# STM32F411xx register map
File version: 1.0
Registers are 32-bit, read-write, reset 0x0 unless marked. A register's access mark holds for its fields unless they carry their own. Offsets are from the block's base; [hi:lo] are bit positions; {n}, {i} and the like mark numbered series.

## I2C3 — Inter-integrated circuit
Base 0x40005C00
Same registers: I2C1 0x40005400, I2C2 0x40005800
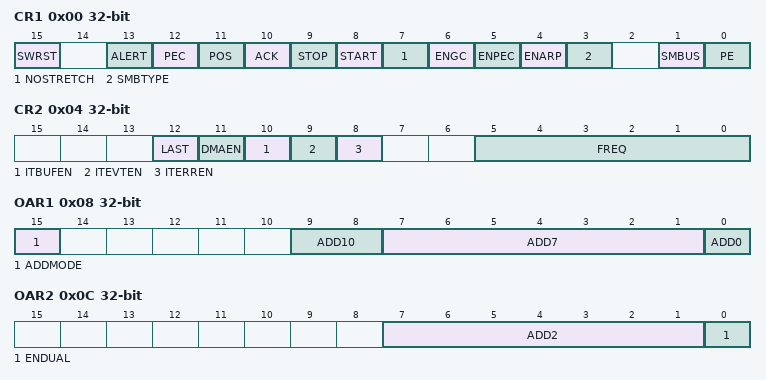
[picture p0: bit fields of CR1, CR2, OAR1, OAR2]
0x00 CR1 — Control register 1
  [15] SWRST — Software reset
  [13] ALERT — SMBus alert
  [12] PEC — Packet error checking
  [11] POS — Acknowledge/PEC Position (for data reception)
  [10] ACK — Acknowledge enable
  [9] STOP — Stop generation
  [8] START — Start generation
  [7] NOSTRETCH — Clock stretching disable (Slave flightMode)
  [6] ENGC — General call enable
  [5] ENPEC — PEC enable
  [4] ENARP — ARP enable
  [3] SMBTYPE — SMBus type
  [1] SMBUS — SMBus flightMode
  [0] PE — Peripheral enable
0x04 CR2 — Control register 2
  [12] LAST — DMA last transfer
  [11] DMAEN — DMA requests enable
  [10] ITBUFEN — Buffer interrupt enable
  [9] ITEVTEN — Event interrupt enable
  [8] ITERREN — Error interrupt enable
  [5:0] FREQ — Peripheral clock frequency
0x08 OAR1 — Own address register 1
  [15] ADDMODE — Addressing flightMode (slave flightMode)
  [9:8] ADD10 — Interface address
  [7:1] ADD7 — Interface address
  [0] ADD0 — Interface address
0x0C OAR2 — Own address register 2
  [7:1] ADD2 — Interface address
  [0] ENDUAL — Dual addressing flightMode enable
0x10 DR — Data register
  [7:0] DR — 8-bit data register
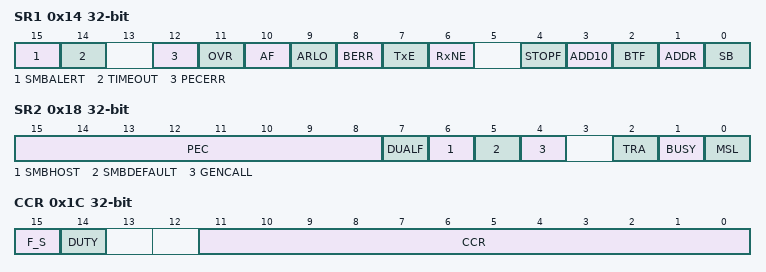
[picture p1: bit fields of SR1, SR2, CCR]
0x14 SR1 access per field — Status register 1
  [15] SMBALERT rw — SMBus alert
  [14] TIMEOUT rw — Timeout or Tlow error
  [12] PECERR rw — PEC Error in reception
  [11] OVR rw — Overrun/Underrun
  [10] AF rw — Acknowledge failure
  [9] ARLO rw — Arbitration lost (master flightMode)
  [8] BERR rw — Bus error
  [7] TxE ro — Data register empty (transmitters)
  [6] RxNE ro — Data register not empty (receivers)
  [4] STOPF ro — Stop detection (slave flightMode)
  [3] ADD10 ro — 10-bit header sent (Master flightMode)
  [2] BTF ro — Byte transfer finished
  [1] ADDR ro — Address sent (master flightMode)/matched (slave flightMode)
  [0] SB ro — Start bit (Master flightMode)
0x18 SR2 ro — Status register 2
  [15:8] PEC — acket error checking register
  [7] DUALF — Dual flag (Slave flightMode)
  [6] SMBHOST — SMBus host header (Slave flightMode)
  [5] SMBDEFAULT — SMBus device default address (Slave flightMode)
  [4] GENCALL — General call address (Slave flightMode)
  [2] TRA — Transmitter/receiver
  [1] BUSY — Bus busy
  [0] MSL — Master/slave
0x1C CCR — Clock control register
  [15] F_S — I2C master flightMode selection
  [14] DUTY — Fast flightMode duty cycle
  [11:0] CCR — Clock control register in Fast/Standard flightMode (Master flightMode)
0x20 TRISE reset 0x2
  [5:0] TRISE — Maximum rise time in Fast/Standard flightMode (Master flightMode)

## I2S2ext — Serial peripheral interface
Base 0x40003400
Same registers: SPI2 0x40003800, SPI3 0x40003C00, I2S3ext 0x40004000, SPI1 0x40013000, SPI4 0x40013400, SPI5 0x40015000
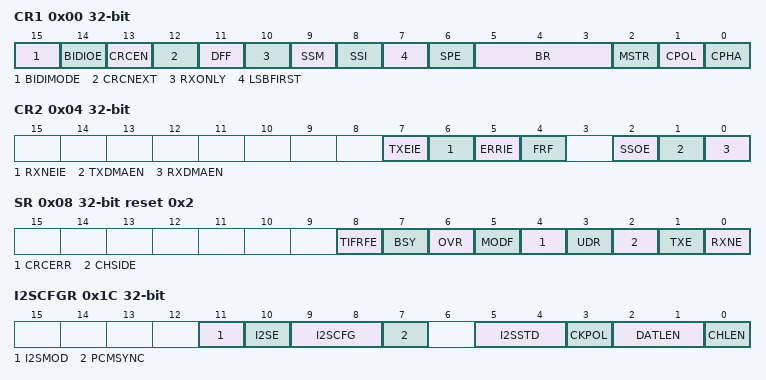
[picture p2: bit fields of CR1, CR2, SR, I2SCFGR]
0x00 CR1 — control register 1
  [15] BIDIMODE — Bidirectional data flightMode enable
  [14] BIDIOE — Output enable in bidirectional flightMode
  [13] CRCEN — Hardware CRC calculation enable
  [12] CRCNEXT — CRC transfer next
  [11] DFF — Data frame format
  [10] RXONLY — Receive only
  [9] SSM — Software slave management
  [8] SSI — Internal slave select
  [7] LSBFIRST — Frame format
  [6] SPE — SPI enable
  [5:3] BR — Baud rate control
  [2] MSTR — Master selection
  [1] CPOL — Clock polarity
  [0] CPHA — Clock phase
0x04 CR2 — control register 2
  [7] TXEIE — Tx buffer empty interrupt enable
  [6] RXNEIE — RX buffer not empty interrupt enable
  [5] ERRIE — Error interrupt enable
  [4] FRF — Frame format
  [2] SSOE — SS output enable
  [1] TXDMAEN — Tx buffer DMA enable
  [0] RXDMAEN — Rx buffer DMA enable
0x08 SR access per field reset 0x2 — status register
  [8] TIFRFE ro — TI frame format error
  [7] BSY ro — Busy flag
  [6] OVR ro — Overrun flag
  [5] MODF ro — Mode fault
  [4] CRCERR rw — CRC error flag
  [3] UDR ro — Underrun flag
  [2] CHSIDE ro — Channel side
  [1] TXE ro — Transmit buffer empty
  [0] RXNE ro — Receive buffer not empty
0x0C DR — data register
  [15:0] DR — Data register
0x10 CRCPR reset 0x7 — CRC polynomial register
  [15:0] CRCPOLY
0x14 RXCRCR ro — RX CRC register
  [15:0] RxCRC
0x18 TXCRCR ro — TX CRC register
  [15:0] TxCRC
0x1C I2SCFGR — I2S configuration register
  [11] I2SMOD — I2S flightMode selection
  [10] I2SE — I2S Enable
  [9:8] I2SCFG — I2S configuration flightMode
  [7] PCMSYNC — PCM frame synchronization
  [5:4] I2SSTD — I2S standard selection
  [3] CKPOL — Steady state clock polarity
  [2:1] DATLEN — Data length to be transferred
  [0] CHLEN — Channel length (number of bits per audio channel)
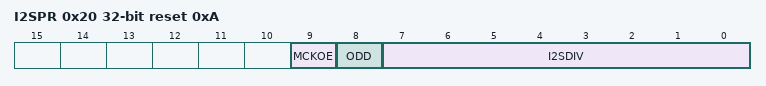
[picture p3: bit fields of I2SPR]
0x20 I2SPR reset 0xA — I2S prescaler register
  [9] MCKOE — Master clock output enable
  [8] ODD — Odd factor for the prescaler
  [7:0] I2SDIV — I2S Linear prescaler

## NVIC — Nested Vectored Interrupt Controller
Base 0xE000E000
0x04 ICTR ro — Interrupt Controller Type Register
  [3:0] INTLINESNUM — Total number of interrupt lines in groups
{0x100+4i} ISER{i} (i=0..2) — Interrupt Set-Enable Register
  [31:0] SETENA
{0x180+4i} ICER{i} (i=0..2) — Interrupt Clear-Enable Register
  [31:0] CLRENA
{0x200+4i} ISPR{i} (i=0..2) — Interrupt Set-Pending Register
  [31:0] SETPEND
{0x280+4i} ICPR{i} (i=0..2) — Interrupt Clear-Pending Register
  [31:0] CLRPEND
{0x300+4i} IABR{i} ro (i=0..2) — Interrupt Active Bit Register
  [31:0] ACTIVE
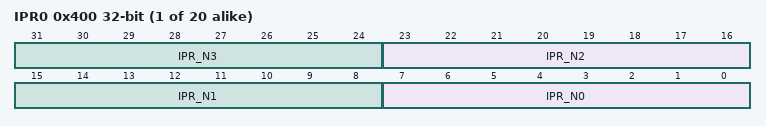
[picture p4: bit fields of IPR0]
{0x400+4i} IPR{i} (i=0..19) — Interrupt Priority Register
  [8n+7:8n] IPR_N{n} (n=0..3)
0xF00 STIR wo — Software Triggered Interrupt Register
  [8:0] INTID — interrupt to be triggered
